AUTOSAR XML (schema 00046)
package /Runnable_Lab1
  sender receiver interface SRI_Throttle
    data CMD: type=uint32
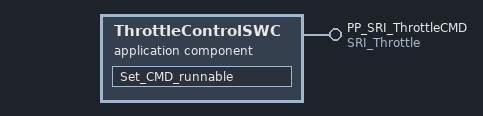
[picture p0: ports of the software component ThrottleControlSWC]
  application sw component type ThrottleControlSWC
    provide port PP_SRI_ThrottleCMD: provided-interface=SRI_Throttle
    behavior ThrottleController_Behavior
      runnable Set_CMD_runnable: symbol=Set_CMD
        data-write-access:
          access CMD_Data: accessed-variable=PP_SRI_ThrottleCMD.CMD
